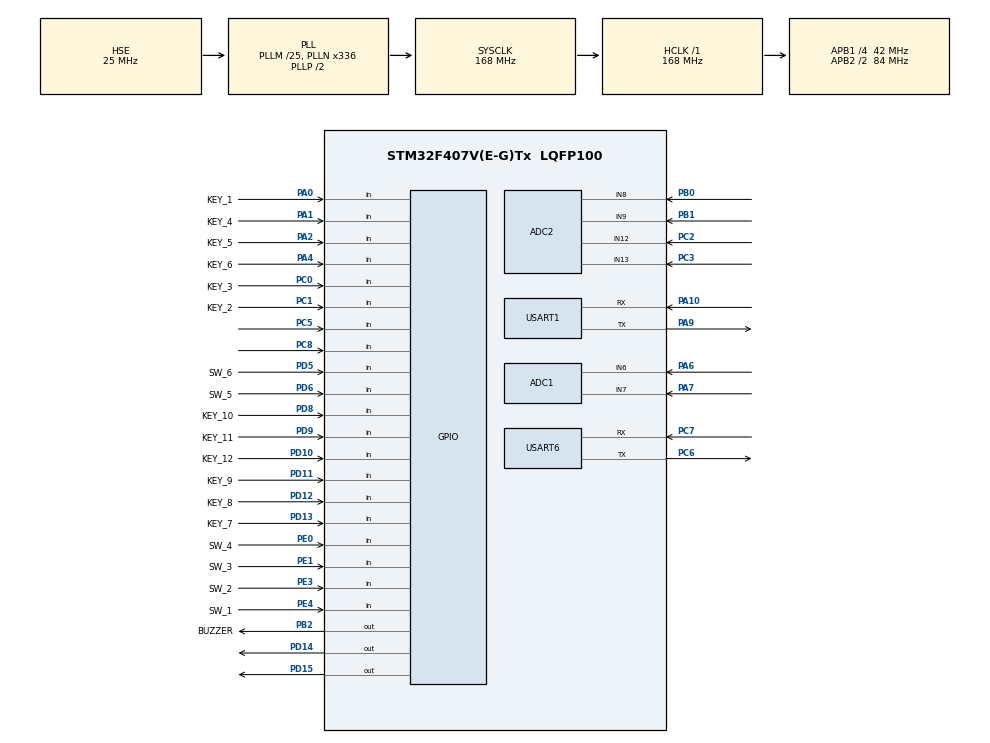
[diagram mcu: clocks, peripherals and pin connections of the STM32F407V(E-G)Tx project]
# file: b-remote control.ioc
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ADC1.Channel-0\#ChannelRegularConversion=ADC_CHANNEL_6
ADC1.Channel-1\#ChannelRegularConversion=ADC_CHANNEL_7
ADC1.ContinuousConvMode=ENABLE
ADC1.DMAContinuousRequests=ENABLE
ADC1.EOCSelection=ADC_EOC_SEQ_CONV
ADC1.NbrOfConversionFlag=2
ADC1.Rank-0\#ChannelRegularConversion=1
ADC1.Rank-1\#ChannelRegularConversion=2
ADC1.SamplingTime-0\#ChannelRegularConversion=ADC_SAMPLETIME_84CYCLES
ADC1.SamplingTime-1\#ChannelRegularConversion=ADC_SAMPLETIME_84CYCLES
ADC1.ScanConvMode=ENABLE
ADC1.master=1
ADC2.Channel-0\#ChannelRegularConversion=ADC_CHANNEL_12
ADC2.Channel-1\#ChannelRegularConversion=ADC_CHANNEL_13
ADC2.Channel-2\#ChannelRegularConversion=ADC_CHANNEL_8
ADC2.Channel-3\#ChannelRegularConversion=ADC_CHANNEL_9
ADC2.ContinuousConvMode=ENABLE
ADC2.DMAContinuousRequests=ENABLE
ADC2.EOCSelection=ADC_EOC_SEQ_CONV
ADC2.NbrOfConversionFlag=4
ADC2.Rank-0\#ChannelRegularConversion=1
ADC2.Rank-1\#ChannelRegularConversion=2
ADC2.Rank-2\#ChannelRegularConversion=3
ADC2.Rank-3\#ChannelRegularConversion=4
ADC2.SamplingTime-0\#ChannelRegularConversion=ADC_SAMPLETIME_84CYCLES
ADC2.SamplingTime-1\#ChannelRegularConversion=ADC_SAMPLETIME_84CYCLES
ADC2.SamplingTime-2\#ChannelRegularConversion=ADC_SAMPLETIME_84CYCLES
ADC2.SamplingTime-3\#ChannelRegularConversion=ADC_SAMPLETIME_84CYCLES
ADC2.ScanConvMode=ENABLE
Dma.ADC1.2.Direction=DMA_PERIPH_TO_MEMORY
Dma.ADC1.2.FIFOMode=DMA_FIFOMODE_DISABLE
Dma.ADC1.2.Instance=DMA2_Stream4
Dma.ADC1.2.MemDataAlignment=DMA_MDATAALIGN_HALFWORD
Dma.ADC1.2.MemInc=DMA_MINC_ENABLE
Dma.ADC1.2.Mode=DMA_CIRCULAR
Dma.ADC1.2.PeriphDataAlignment=DMA_PDATAALIGN_HALFWORD
Dma.ADC1.2.PeriphInc=DMA_PINC_DISABLE
Dma.ADC1.2.Priority=DMA_PRIORITY_HIGH
Dma.ADC2.3.Direction=DMA_PERIPH_TO_MEMORY
Dma.ADC2.3.FIFOMode=DMA_FIFOMODE_DISABLE
Dma.ADC2.3.Instance=DMA2_Stream3
Dma.ADC2.3.MemDataAlignment=DMA_MDATAALIGN_HALFWORD
Dma.ADC2.3.MemInc=DMA_MINC_ENABLE
Dma.ADC2.3.Mode=DMA_CIRCULAR
Dma.ADC2.3.PeriphDataAlignment=DMA_PDATAALIGN_HALFWORD
Dma.ADC2.3.PeriphInc=DMA_PINC_DISABLE
Dma.ADC2.3.Priority=DMA_PRIORITY_HIGH
Dma.Request0=USART1_TX
Dma.Request1=USART1_RX
Dma.Request2=ADC1
Dma.Request3=ADC2
Dma.USART1_RX.1.Direction=DMA_PERIPH_TO_MEMORY
Dma.USART1_RX.1.FIFOMode=DMA_FIFOMODE_DISABLE
Dma.USART1_RX.1.Instance=DMA2_Stream2
Dma.USART1_RX.1.MemDataAlignment=DMA_MDATAALIGN_BYTE
Dma.USART1_RX.1.MemInc=DMA_MINC_ENABLE
Dma.USART1_RX.1.Mode=DMA_NORMAL
Dma.USART1_RX.1.PeriphDataAlignment=DMA_PDATAALIGN_BYTE
Dma.USART1_RX.1.PeriphInc=DMA_PINC_DISABLE
Dma.USART1_RX.1.Priority=DMA_PRIORITY_LOW
Dma.USART1_TX.0.Direction=DMA_MEMORY_TO_PERIPH
Dma.USART1_TX.0.FIFOMode=DMA_FIFOMODE_DISABLE
Dma.USART1_TX.0.Instance=DMA2_Stream7
Dma.USART1_TX.0.MemDataAlignment=DMA_MDATAALIGN_BYTE
Dma.USART1_TX.0.MemInc=DMA_MINC_ENABLE
Dma.USART1_TX.0.Mode=DMA_NORMAL
Dma.USART1_TX.0.PeriphDataAlignment=DMA_PDATAALIGN_BYTE
Dma.USART1_TX.0.PeriphInc=DMA_PINC_DISABLE
Dma.USART1_TX.0.Priority=DMA_PRIORITY_LOW
FREERTOS.Tasks01=remoteTask,32,256,StartRemoteTask,Default,NULL,Dynamic,NULL,NULL
FREERTOS.Tasks02=debugTask,16,256,StartDebugTask,Default,NULL,Dynamic,NULL,NULL
Mcu.Family=STM32F4
Mcu.Name=STM32F407V(E-G)Tx
Mcu.Package=LQFP100
NVIC.DMA2_Stream2_IRQn=true\:5\:0\:false\:false\:true\:true\:false\:true\:true
NVIC.DMA2_Stream3_IRQn=true\:5\:0\:false\:false\:true\:true\:false\:true\:true
NVIC.DMA2_Stream4_IRQn=true\:5\:0\:false\:false\:true\:true\:false\:true\:true
NVIC.DMA2_Stream7_IRQn=true\:5\:0\:false\:false\:true\:true\:false\:true\:true
NVIC.PriorityGroup=NVIC_PRIORITYGROUP_4
NVIC.USART1_IRQn=true\:5\:0\:false\:false\:true\:true\:false\:true\:true
PA0-WKUP.GPIO_Label=KEY_1
PA0-WKUP.GPIO_PuPd=GPIO_NOPULL
PA0-WKUP.Signal=GPIO_Input
PA1.GPIO_Label=KEY_4
PA1.GPIO_PuPd=GPIO_NOPULL
PA1.Signal=GPIO_Input
PA10.Mode=Asynchronous
PA10.Signal=USART1_RX
PA13.Mode=Serial_Wire
PA13.Signal=SYS_JTMS-SWDIO
PA14.Mode=Serial_Wire
PA14.Signal=SYS_JTCK-SWCLK
PA2.GPIO_Label=KEY_5
PA2.GPIO_PuPd=GPIO_NOPULL
PA2.Signal=GPIO_Input
PA4.GPIO_Label=KEY_6
PA4.GPIO_PuPd=GPIO_NOPULL
PA4.Signal=GPIO_Input
PA6.Signal=ADCx_IN6
PA7.Signal=ADCx_IN7
PA9.Mode=Asynchronous
PA9.Signal=USART1_TX
PB0.Signal=ADCx_IN8
PB1.Signal=ADCx_IN9
PB2.GPIO_Label=BUZZER
PB2.GPIO_ModeDefaultOutputPP=GPIO_MODE_OUTPUT_PP
PB2.GPIO_PuPd=GPIO_NOPULL
PB2.Signal=GPIO_Output
PC0.GPIO_Label=KEY_3
PC0.GPIO_PuPd=GPIO_NOPULL
PC0.Signal=GPIO_Input
PC1.GPIO_Label=KEY_2
PC1.GPIO_PuPd=GPIO_NOPULL
PC1.Signal=GPIO_Input
PC2.Signal=ADCx_IN12
PC3.Signal=ADCx_IN13
PC5.Signal=GPIO_Input
PC6.Mode=Asynchronous
PC6.Signal=USART6_TX
PC7.Mode=Asynchronous
PC7.Signal=USART6_RX
PC8.Signal=GPIO_Input
PD10.GPIO_Label=KEY_12
PD10.GPIO_PuPd=GPIO_NOPULL
PD10.Signal=GPIO_Input
PD11.GPIO_Label=KEY_9
PD11.GPIO_PuPd=GPIO_NOPULL
PD11.Signal=GPIO_Input
PD12.GPIO_Label=KEY_8
PD12.GPIO_PuPd=GPIO_NOPULL
PD12.Signal=GPIO_Input
PD13.GPIO_Label=KEY_7
PD13.GPIO_PuPd=GPIO_NOPULL
PD13.Signal=GPIO_Input
PD14.Signal=GPIO_Output
PD15.Signal=GPIO_Output
PD5.GPIO_Label=SW_6
PD5.GPIO_PuPd=GPIO_NOPULL
PD5.Signal=GPIO_Input
PD6.GPIO_Label=SW_5
PD6.GPIO_PuPd=GPIO_NOPULL
PD6.Signal=GPIO_Input
PD8.GPIO_Label=KEY_10
PD8.GPIO_PuPd=GPIO_NOPULL
PD8.Signal=GPIO_Input
PD9.GPIO_Label=KEY_11
PD9.GPIO_PuPd=GPIO_NOPULL
PD9.Signal=GPIO_Input
PE0.GPIO_Label=SW_4
PE0.GPIO_PuPd=GPIO_NOPULL
PE0.Signal=GPIO_Input
PE1.GPIO_Label=SW_3
PE1.GPIO_PuPd=GPIO_NOPULL
PE1.Signal=GPIO_Input
PE3.GPIO_Label=SW_2
PE3.GPIO_PuPd=GPIO_NOPULL
PE3.Signal=GPIO_Input
PE4.GPIO_Label=SW_1
PE4.GPIO_PuPd=GPIO_NOPULL
PE4.Signal=GPIO_Input
PH0-OSC_IN.Mode=HSE-External-Oscillator
PH0-OSC_IN.Signal=RCC_OSC_IN
PH1-OSC_OUT.Mode=HSE-External-Oscillator
PH1-OSC_OUT.Signal=RCC_OSC_OUT
ProjectManager.HeapSize=0x200
ProjectManager.StackSize=0x400
ProjectManager.TargetToolchain=MDK-ARM V5.32
RCC.48MHZClocksFreq_Value=84000000
RCC.AHBFreq_Value=168000000
RCC.APB1CLKDivider=RCC_HCLK_DIV4
RCC.APB1Freq_Value=42000000
RCC.APB1TimFreq_Value=84000000
RCC.APB2CLKDivider=RCC_HCLK_DIV2
RCC.APB2Freq_Value=84000000
RCC.APB2TimFreq_Value=168000000
RCC.CortexFreq_Value=168000000
RCC.HCLKFreq_Value=168000000
RCC.HSE_VALUE=25000000
RCC.HSI_VALUE=16000000
RCC.LSE_VALUE=32768
RCC.PLLM=25
RCC.PLLN=336
RCC.PLLSourceVirtual=RCC_PLLSOURCE_HSE
RCC.SYSCLKFreq_VALUE=168000000
RCC.SYSCLKSource=RCC_SYSCLKSOURCE_PLLCLK
RCC.VCOOutputFreq_Value=336000000
SH.ADCx_IN12.0=ADC2_IN12,IN12
SH.ADCx_IN13.0=ADC2_IN13,IN13
SH.ADCx_IN6.0=ADC1_IN6,IN6
SH.ADCx_IN7.0=ADC1_IN7,IN7
SH.ADCx_IN8.0=ADC2_IN8,IN8
SH.ADCx_IN9.0=ADC2_IN9,IN9
USART1.VirtualMode=VM_ASYNC
USART6.VirtualMode=VM_ASYNC
VP_FREERTOS_VS_CMSIS_V2.Mode=CMSIS_V2
board=custom

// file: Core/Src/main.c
/* USER CODE BEGIN Header */
/**
  ******************************************************************************
  * @file           : main.c
  * @brief          : Main program body
  ******************************************************************************
  * @attention
  *
  * Copyright (c) 2026 STMicroelectronics.
  * All rights reserved.
  *
  * This software is licensed under terms that can be found in the LICENSE file
  * in the root directory of this software component.
  * If no LICENSE file comes with this software, it is provided AS-IS.
  *
  ******************************************************************************
  */
/* USER CODE END Header */
#include "main.h"
#include "cmsis_os.h"
#include "adc.h"
#include "dma.h"
#include "usart.h"
#include "gpio.h"

/* USER CODE BEGIN Includes */
#include "mymain.h"

/* USER CODE END Includes */

void SystemClock_Config(void);
void MX_FREERTOS_Init(void);

int main(void)
{

  /* MCU Configuration--------------------------------------------------------*/

  /* Reset of all peripherals, Initializes the Flash interface and the Systick. */
  HAL_Init();

  /* Configure the system clock */
  SystemClock_Config();

  /* Initialize all configured peripherals */
  MX_GPIO_Init();
  MX_DMA_Init();
  MX_ADC1_Init();
  MX_ADC2_Init();
  MX_USART1_UART_Init();
  MX_USART6_UART_Init();
  /* USER CODE BEGIN 2 */
  MyMain_Init();

  /* USER CODE END 2 */

  /* Init scheduler */
  osKernelInitialize();  /* Call init function for freertos objects (in cmsis_os2.c) */
  MX_FREERTOS_Init();

  /* Start scheduler */
  osKernelStart();

  /* We should never get here as control is now taken by the scheduler */

  /* Infinite loop */
  while (1)
  {

  }
}

void SystemClock_Config(void)
{
  RCC_OscInitTypeDef RCC_OscInitStruct = {0};
  RCC_ClkInitTypeDef RCC_ClkInitStruct = {0};

  /** Configure the main internal regulator output voltage
  */
  __HAL_RCC_PWR_CLK_ENABLE();
  __HAL_PWR_VOLTAGESCALING_CONFIG(PWR_REGULATOR_VOLTAGE_SCALE1);

  /** Initializes the RCC Oscillators according to the specified parameters
  * in the RCC_OscInitTypeDef structure.
  */
  RCC_OscInitStruct.OscillatorType = RCC_OSCILLATORTYPE_HSE;
  RCC_OscInitStruct.HSEState = RCC_HSE_ON;
  RCC_OscInitStruct.PLL.PLLState = RCC_PLL_ON;
  RCC_OscInitStruct.PLL.PLLSource = RCC_PLLSOURCE_HSE;
  RCC_OscInitStruct.PLL.PLLM = 25;
  RCC_OscInitStruct.PLL.PLLN = 336;
  RCC_OscInitStruct.PLL.PLLP = RCC_PLLP_DIV2;
  RCC_OscInitStruct.PLL.PLLQ = 4;
  if (HAL_RCC_OscConfig(&RCC_OscInitStruct) != HAL_OK)
  {
    Error_Handler();
  }

  /** Initializes the CPU, AHB and APB buses clocks
  */
  RCC_ClkInitStruct.ClockType = RCC_CLOCKTYPE_HCLK|RCC_CLOCKTYPE_SYSCLK
                              |RCC_CLOCKTYPE_PCLK1|RCC_CLOCKTYPE_PCLK2;
  RCC_ClkInitStruct.SYSCLKSource = RCC_SYSCLKSOURCE_PLLCLK;
  RCC_ClkInitStruct.AHBCLKDivider = RCC_SYSCLK_DIV1;
  RCC_ClkInitStruct.APB1CLKDivider = RCC_HCLK_DIV4;
  RCC_ClkInitStruct.APB2CLKDivider = RCC_HCLK_DIV2;

  if (HAL_RCC_ClockConfig(&RCC_ClkInitStruct, FLASH_LATENCY_5) != HAL_OK)
  {
    Error_Handler();
  }
}

void Error_Handler(void)
{
  __disable_irq();
  while (1)
  {
  }
}

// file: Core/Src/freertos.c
/* USER CODE BEGIN Header */
/**
  ******************************************************************************
  * File Name          : freertos.c
  * Description        : Code for freertos applications
  ******************************************************************************
  * @attention
  *
  * Copyright (c) 2026 STMicroelectronics.
  * All rights reserved.
  *
  * This software is licensed under terms that can be found in the LICENSE file
  * in the root directory of this software component.
  * If no LICENSE file comes with this software, it is provided AS-IS.
  *
  ******************************************************************************
  */
/* USER CODE END Header */

#include "FreeRTOS.h"
#include "task.h"
#include "main.h"
#include "cmsis_os.h"

/* USER CODE BEGIN Includes */
#include "mymain.h"
#include "RemoteInput.h"

/* USER CODE END Includes */

/* Definitions for remoteTask */
osThreadId_t remoteTaskHandle;
const osThreadAttr_t remoteTask_attributes = {
  .name = "remoteTask",
  .stack_size = 256 * 4,
  .priority = (osPriority_t) osPriorityAboveNormal,
};
/* Definitions for debugTask */
osThreadId_t debugTaskHandle;
const osThreadAttr_t debugTask_attributes = {
  .name = "debugTask",
  .stack_size = 256 * 4,
  .priority = (osPriority_t) osPriorityBelowNormal,
};

void StartRemoteTask(void *argument);
void StartDebugTask(void *argument);

void MX_FREERTOS_Init(void); /* (MISRA C 2004 rule 8.1) */

void MX_FREERTOS_Init(void) {

  /* Create the thread(s) */
  /* creation of remoteTask */
  remoteTaskHandle = osThreadNew(StartRemoteTask, NULL, &remoteTask_attributes);

  /* creation of debugTask */
  debugTaskHandle = osThreadNew(StartDebugTask, NULL, &debugTask_attributes);

}

void StartRemoteTask(void *argument)
{
  /* USER CODE BEGIN StartRemoteTask */
  (void)argument;

  /* Infinite loop */
  for(;;)
  {
    Remote_Update();
    osDelay(1);
  }
  /* USER CODE END StartRemoteTask */
}

void StartDebugTask(void *argument)
{
  /* USER CODE BEGIN StartDebugTask */
  (void)argument;

  /* Infinite loop */
  for(;;)
  {
    MyMain_Debug();
    osDelay(1);
  }
  /* USER CODE END StartDebugTask */
}
